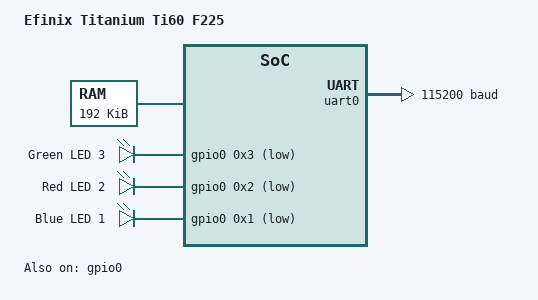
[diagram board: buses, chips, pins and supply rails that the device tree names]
/dts-v1/;

/* node '/' defined in zephyr/dts/riscv/efinix/sapphire_soc.dtsi:10 */
/ {
	#address-cells = < 0x1 >;                 /* in zephyr/dts/riscv/efinix/sapphire_soc.dtsi:11 */
	#size-cells = < 0x1 >;                    /* in zephyr/dts/riscv/efinix/sapphire_soc.dtsi:12 */
	model = "Efinix Titanium Ti60 F225";      /* in zephyr/boards/efinix/titanium_ti60_f225/titanium_ti60_f225.dts:12 */
	compatible = "efinix,titanium-ti60-f225"; /* in zephyr/boards/efinix/titanium_ti60_f225/titanium_ti60_f225.dts:13 */

	/* node '/chosen' defined in zephyr/dts/riscv/efinix/sapphire_soc.dtsi:16 */
	chosen {
		zephyr,console = &uart0;    /* in zephyr/boards/efinix/titanium_ti60_f225/titanium_ti60_f225.dts:16 */
		zephyr,shell-uart = &uart0; /* in zephyr/boards/efinix/titanium_ti60_f225/titanium_ti60_f225.dts:17 */
		zephyr,sram = &ram0;        /* in zephyr/boards/efinix/titanium_ti60_f225/titanium_ti60_f225.dts:18 */
	};

	/* node '/memory@F9000000' defined in zephyr/dts/riscv/efinix/sapphire_soc.dtsi:20 */
	ram0: memory@F9000000 {
		device_type = "memory";       /* in zephyr/dts/riscv/efinix/sapphire_soc.dtsi:21 */
		reg = < 0xf9000000 0x30000 >; /* in zephyr/dts/riscv/efinix/sapphire_soc.dtsi:22 */
	};

	/* node '/cpus' defined in zephyr/dts/riscv/efinix/sapphire_soc.dtsi:25 */
	cpus {
		#address-cells = < 0x1 >; /* in zephyr/dts/riscv/efinix/sapphire_soc.dtsi:26 */
		#size-cells = < 0x0 >;    /* in zephyr/dts/riscv/efinix/sapphire_soc.dtsi:27 */

		/* node '/cpus/cpu@0' defined in zephyr/dts/riscv/efinix/sapphire_soc.dtsi:29 */
		cpu@0 {
			clock-frequency = < 0x5f5e100 >;         /* in zephyr/dts/riscv/efinix/sapphire_soc.dtsi:30 */
			compatible = "efinix,vexriscv-sapphire",
			             "riscv";                    /* in zephyr/dts/riscv/efinix/sapphire_soc.dtsi:31 */
			device_type = "cpu";                     /* in zephyr/dts/riscv/efinix/sapphire_soc.dtsi:32 */
			reg = < 0x0 >;                           /* in zephyr/dts/riscv/efinix/sapphire_soc.dtsi:33 */
			riscv,isa = "rv32ima_zicsr_zifencei";    /* in zephyr/dts/riscv/efinix/sapphire_soc.dtsi:34 */
			status = "okay";                         /* in zephyr/dts/riscv/efinix/sapphire_soc.dtsi:35 */

			/* node '/cpus/cpu@0/interrupt-controller' defined in zephyr/dts/riscv/efinix/sapphire_soc.dtsi:37 */
			hlic: interrupt-controller {
				compatible = "riscv,cpu-intc"; /* in zephyr/dts/riscv/efinix/sapphire_soc.dtsi:38 */
				#address-cells = < 0x0 >;      /* in zephyr/dts/riscv/efinix/sapphire_soc.dtsi:39 */
				#interrupt-cells = < 0x1 >;    /* in zephyr/dts/riscv/efinix/sapphire_soc.dtsi:40 */
				interrupt-controller;          /* in zephyr/dts/riscv/efinix/sapphire_soc.dtsi:41 */
				phandle = < 0x1 >;             /* in zephyr/dts/riscv/efinix/sapphire_soc.dtsi:57 */
			};
		};
	};

	/* node '/soc' defined in zephyr/dts/riscv/efinix/sapphire_soc.dtsi:46 */
	soc {
		#address-cells = < 0x1 >;       /* in zephyr/dts/riscv/efinix/sapphire_soc.dtsi:47 */
		#size-cells = < 0x1 >;          /* in zephyr/dts/riscv/efinix/sapphire_soc.dtsi:48 */
		compatible = "efinix,sapphire"; /* in zephyr/dts/riscv/efinix/sapphire_soc.dtsi:49 */
		ranges;                         /* in zephyr/dts/riscv/efinix/sapphire_soc.dtsi:50 */

		/* node '/soc/interrupt-controller@f8c00000' defined in zephyr/dts/riscv/efinix/sapphire_soc.dtsi:52 */
		plic0: interrupt-controller@f8c00000 {
			compatible = "sifive,plic-1.0.0";    /* in zephyr/dts/riscv/efinix/sapphire_soc.dtsi:53 */
			#address-cells = < 0x0 >;            /* in zephyr/dts/riscv/efinix/sapphire_soc.dtsi:54 */
			#interrupt-cells = < 0x2 >;          /* in zephyr/dts/riscv/efinix/sapphire_soc.dtsi:55 */
			interrupt-controller;                /* in zephyr/dts/riscv/efinix/sapphire_soc.dtsi:56 */
			interrupts-extended = < &hlic 0xb >; /* in zephyr/dts/riscv/efinix/sapphire_soc.dtsi:57 */
			reg = < 0xf8c00000 0x400000 >;       /* in zephyr/dts/riscv/efinix/sapphire_soc.dtsi:58 */
			riscv,max-priority = < 0x3 >;        /* in zephyr/dts/riscv/efinix/sapphire_soc.dtsi:59 */
			riscv,ndev = < 0x20 >;               /* in zephyr/dts/riscv/efinix/sapphire_soc.dtsi:60 */
			phandle = < 0x2 >;                   /* in zephyr/dts/riscv/efinix/sapphire_soc.dtsi:79 */
		};

		/* node '/soc/clint@f8b00000' defined in zephyr/dts/riscv/efinix/sapphire_soc.dtsi:63 */
		clint: clint@f8b00000 {
			compatible = "sifive,clint0";                  /* in zephyr/dts/riscv/efinix/sapphire_soc.dtsi:64 */
			interrupts-extended = < &hlic 0x3 &hlic 0x7 >; /* in zephyr/dts/riscv/efinix/sapphire_soc.dtsi:65 */
			reg = < 0xf8b00000 0x10000 >;                  /* in zephyr/dts/riscv/efinix/sapphire_soc.dtsi:66 */
		};

		/* node '/soc/timer@f8b0bff8' defined in zephyr/dts/riscv/efinix/sapphire_soc.dtsi:69 */
		mtimer: timer@f8b0bff8 {
			compatible = "riscv,machine-timer";      /* in zephyr/dts/riscv/efinix/sapphire_soc.dtsi:70 */
			interrupts-extended = < &hlic 0x7 >;     /* in zephyr/dts/riscv/efinix/sapphire_soc.dtsi:71 */
			reg = < 0xf8b0bff8 0x8 0xf8b04000 0x8 >; /* in zephyr/dts/riscv/efinix/sapphire_soc.dtsi:72 */
			reg-names = "mtime",
			            "mtimecmp";                  /* in zephyr/dts/riscv/efinix/sapphire_soc.dtsi:73 */
		};

		/* node '/soc/timer@e0002800' defined in zephyr/dts/riscv/efinix/sapphire_soc.dtsi:76 */
		timer0: timer@e0002800 {
			compatible = "efinix,sapphire-timer0"; /* in zephyr/dts/riscv/efinix/sapphire_soc.dtsi:77 */
			reg = < 0xe0002800 0x40 >;             /* in zephyr/dts/riscv/efinix/sapphire_soc.dtsi:78 */
			interrupt-parent = < &plic0 >;         /* in zephyr/dts/riscv/efinix/sapphire_soc.dtsi:79 */
			interrupts = < 0x13 0x0 >;             /* in zephyr/dts/riscv/efinix/sapphire_soc.dtsi:80 */
			status = "disabled";                   /* in zephyr/dts/riscv/efinix/sapphire_soc.dtsi:81 */
		};

		/* node '/soc/gpio@f8015000' defined in zephyr/dts/riscv/efinix/sapphire_soc.dtsi:84 */
		gpio0: gpio@f8015000 {
			compatible = "efinix,sapphire-gpio"; /* in zephyr/dts/riscv/efinix/sapphire_soc.dtsi:85 */
			reg = < 0xf8015000 0x100 >;          /* in zephyr/dts/riscv/efinix/sapphire_soc.dtsi:86 */
			reg-names = "base";                  /* in zephyr/dts/riscv/efinix/sapphire_soc.dtsi:87 */
			ngpios = < 0x4 >;                    /* in zephyr/dts/riscv/efinix/sapphire_soc.dtsi:88 */
			gpio-controller;                     /* in zephyr/dts/riscv/efinix/sapphire_soc.dtsi:89 */
			#gpio-cells = < 0x2 >;               /* in zephyr/dts/riscv/efinix/sapphire_soc.dtsi:90 */
			#address-cells = < 0x1 >;            /* in zephyr/dts/riscv/efinix/sapphire_soc.dtsi:91 */
			#size-cells = < 0x1 >;               /* in zephyr/dts/riscv/efinix/sapphire_soc.dtsi:92 */
			status = "okay";                     /* in zephyr/boards/efinix/titanium_ti60_f225/titanium_ti60_f225.dts:51 */
			phandle = < 0x3 >;                   /* in zephyr/boards/efinix/titanium_ti60_f225/titanium_ti60_f225.dts:29 */
		};

		/* node '/soc/uart@f8010000' defined in zephyr/dts/riscv/efinix/sapphire_soc.dtsi:96 */
		uart0: uart@f8010000 {
			compatible = "efinix,sapphire-uart0"; /* in zephyr/dts/riscv/efinix/sapphire_soc.dtsi:97 */
			interrupt-parent = < &plic0 >;        /* in zephyr/dts/riscv/efinix/sapphire_soc.dtsi:98 */
			interrupts = < 0x1 0x1 >;             /* in zephyr/dts/riscv/efinix/sapphire_soc.dtsi:99 */
			reg = < 0xf8010000 0x40 >;            /* in zephyr/dts/riscv/efinix/sapphire_soc.dtsi:100 */
			reg-names = "base";                   /* in zephyr/dts/riscv/efinix/sapphire_soc.dtsi:101 */
			status = "okay";                      /* in zephyr/boards/efinix/titanium_ti60_f225/titanium_ti60_f225.dts:46 */
			current-speed = < 0x1c200 >;          /* in zephyr/boards/efinix/titanium_ti60_f225/titanium_ti60_f225.dts:47 */
		};
	};

	/* node '/aliases' defined in zephyr/boards/efinix/titanium_ti60_f225/titanium_ti60_f225.dts:21 */
	aliases {
		led0 = &green_led; /* in zephyr/boards/efinix/titanium_ti60_f225/titanium_ti60_f225.dts:22 */
	};

	/* node '/leds' defined in zephyr/boards/efinix/titanium_ti60_f225/titanium_ti60_f225.dts:25 */
	leds {
		compatible = "gpio-leds"; /* in zephyr/boards/efinix/titanium_ti60_f225/titanium_ti60_f225.dts:26 */

		/* node '/leds/led_0' defined in zephyr/boards/efinix/titanium_ti60_f225/titanium_ti60_f225.dts:28 */
		green_led: led_0 {
			gpios = < &gpio0 0x3 0x1 >; /* in zephyr/boards/efinix/titanium_ti60_f225/titanium_ti60_f225.dts:29 */
			label = "Green LED 3";      /* in zephyr/boards/efinix/titanium_ti60_f225/titanium_ti60_f225.dts:30 */
		};

		/* node '/leds/led_1' defined in zephyr/boards/efinix/titanium_ti60_f225/titanium_ti60_f225.dts:33 */
		red_led: led_1 {
			gpios = < &gpio0 0x2 0x1 >; /* in zephyr/boards/efinix/titanium_ti60_f225/titanium_ti60_f225.dts:34 */
			label = "Red LED 2";        /* in zephyr/boards/efinix/titanium_ti60_f225/titanium_ti60_f225.dts:35 */
		};

		/* node '/leds/led_2' defined in zephyr/boards/efinix/titanium_ti60_f225/titanium_ti60_f225.dts:38 */
		blue_led: led_2 {
			gpios = < &gpio0 0x1 0x1 >; /* in zephyr/boards/efinix/titanium_ti60_f225/titanium_ti60_f225.dts:39 */
			label = "Blue LED 1";       /* in zephyr/boards/efinix/titanium_ti60_f225/titanium_ti60_f225.dts:40 */
		};
	};
};
